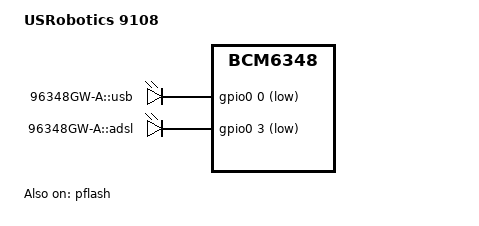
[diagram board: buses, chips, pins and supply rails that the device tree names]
/dts-v1/;

#include "bcm6348.dtsi"

#include <dt-bindings/input/input.h>

/ {
	model = "USRobotics 9108";
	compatible = "usr,9108", "brcm,bcm6348";

	gpio-leds {
		compatible = "gpio-leds";

		usb {
			label = "96348GW-A::usb";
			gpios = <&gpio0 0 1>;
		};
		dsl {
			label = "96348GW-A::adsl";
			gpios = <&gpio0 3 1>;
		};
	};
};

&pflash {
	status = "ok";

	linux,part-probe = "bcm63xxpart";

	cfe@0 {
		label = "CFE";
		reg = <0x000000 0x010000>;
		read-only;
	};

	linux@10000 {
		label = "linux";
		reg = <0x010000 0x3e0000>;
	};

	nvram@3f0000 {
		label = "nvram";
		reg = <0x3f0000 0x010000>;
	};
};
